# ATA5835 device description
Architecture: AVR8; Family: megaAVR
Registers are 8-bit, access not given, no defined reset value unless marked. A register's access mark holds for its fields unless they carry their own. Offsets are from the block's base; [hi:lo] are bit positions.

## RXBUF
Instances: RXBUF 0x00
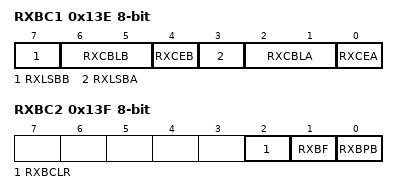
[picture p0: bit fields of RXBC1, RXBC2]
0x13E RXBC1 — Rx Buffer Configuration 1
  [7] RXLSBB — Receive Data LSB-First Path B
  [6:5] RXCBLB — Receive CRC Bit Length Path B
    0=CRC 4-bit; 1=CRC 8-bit; 2=CRC 16-bit
  [4] RXCEB — RX CRC Enable data path B
  [3] RXLSBA — Receive Data LSB-First Path A
  [2:1] RXCBLA — Receive CRC Bit Length Path A
    0=CRC 4-bit; 1=CRC 8-bit; 2=CRC 16-bit
  [0] RXCEA — RX CRC Enable data path A
0x13F RXBC2 — Rx Buffer Configuration 2
  [2] RXBCLR — RX Buffer Clear
  [1] RXBF — RX Buffer Finish
  [0] RXBPB — RX Buffer Path Select
0x140 RXTLLB — Rx Telegram Length Low Byte Path B
0x141 RXTLHB bits used 3:0 — Rx Telegram Length High Byte Path B
0x142 RXCRLB — Rx CRC Result Low Byte Path B
0x143 RXCRHB — Rx CRC Result High Byte Path B
0x144 RXCSBB — Rx CRC Skip Bit Number Path B
0x145 RXCILB — Rx CRC Init Value Low Byte Path B
0x146 RXCIHB — Rx CRC Init Value High Byte Path B
0x147 RXCPLB — Rx CRC Polynomial Low Byte Path B
0x148 RXCPHB — Rx CRC Polynomial High Byte Path B
0x149 RXDSB — Receive Data Shift Register Path B
0x14A RXTLLA — Rx Telegram Length Low Byte Path A
0x14B RXTLHA bits used 3:0 — Rx Telegram Length High Byte Path A
0x14C RXCRLA — Rx CRC Result Low Byte Path A
0x14D RXCRHA — Rx CRC Result High Byte Path A
0x14E RXCSBA — Rx CRC Skip Bit Number Path A
0x14F RXCILA — Rx CRC Init Value Low Byte Path A
0x150 RXCIHA — Rx CRC Init Value High Byte Path A
0x151 RXCPLA — Rx CRC Polynomial Low Byte Path A
0x152 RXCPHA — Rx CRC Polynomial High Byte Path A
0x153 RXDSA — Receive Data Shift Register Path A

## SFIFO
Instances: SFIFO 0x00
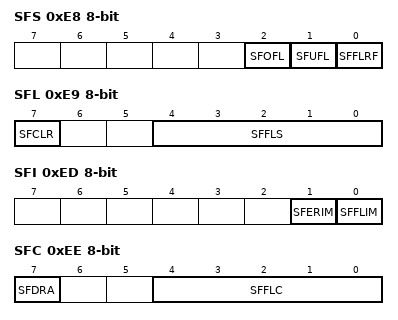
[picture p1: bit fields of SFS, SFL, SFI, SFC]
0xE8 SFS — Support FIFO Status
  [2] SFOFL — Support FIFO Overflow Flag
  [1] SFUFL — Support FIFO Underflow Flag
  [0] SFFLRF — Support FIFO Fill Level Reached Status Flag
0xE9 SFL — Support FIFO Fill Level
  [7] SFCLR — Support FIFO Clear
  [4:0] SFFLS — Support FIFO Fill Level Status
0xEA SFWP bits used 4:0 — Support FIFO Write Pointer
0xEB SFRP bits used 4:0 — Support FIFO Read Pointer
0xEC SFD — Support FIFO Data
0xED SFI — Support FIFO Interrupt Mask
  [1] SFERIM — Support FIFO Error Interrupt Mask
  [0] SFFLIM — Support FIFO Fill Level Interrupt Mask
0xEE SFC — Support FIFO Configuration
  [7] SFDRA — Support FIFO Direct Read Access Operational Mode
  [4:0] SFFLC — Support FIFO Fill Level Configuration

## SPI
Instances: SPI 0x00
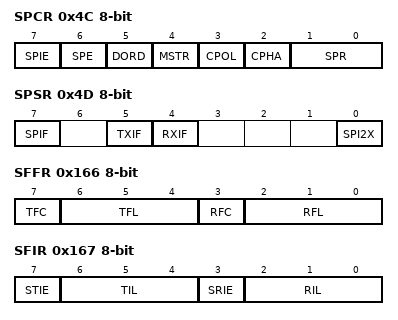
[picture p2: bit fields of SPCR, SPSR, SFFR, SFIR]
0x4C SPCR — SPI Control Register
  [7] SPIE — SPI Interrupt Enable
  [6] SPE — SPI Enable
  [5] DORD — Data Order
  [4] MSTR — Master/Slave Select
  [3] CPOL — Clock Polarity
  [2] CPHA — Clock Phase
  [1:0] SPR — SPI Clock Rate Select
    0=clkio/4; 1=clkio/16; 2=clkio/64; 3=clkio/128; 4=clkio/2; 5=clkio/8; 6=clkio/32; 7=clkio/64
0x4D SPSR — SPI Status Register
  [7] SPIF — SPI Interrupt Flag
  [5] TXIF — Tx Buffer Interrupt Flag
  [4] RXIF — Rx Buffer Interrupt Flag
  [0] SPI2X — Double SPI Speed Bit
0x4E SPDR — SPI Data Register
0x166 SFFR — SPI FIFO Fill Status Register
  [7] TFC — Transmit Buffer Clear
  [6:4] TFL — Transmit Buffer Fill Level
  [3] RFC — Rx Buffer Clear
  [2:0] RFL — Receive Buffer Fill Level
0x167 SFIR — SPI FIFO Interrupt Register
  [7] STIE — SPI Transmit Buffer Interrupt Enable
  [6:4] TIL — Transmit Buffer Interrupt Level
  [3] SRIE — SPI Rx Buffer Interrupt Enable
  [2:0] RIL — Receive Buffer Interrupt Level

## SUP
Instances: SUP 0x00
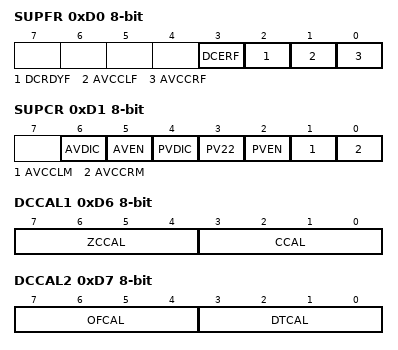
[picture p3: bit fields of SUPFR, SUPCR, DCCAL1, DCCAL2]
0xD0 SUPFR — Supply Flag Register
  [3] DCERF — DCDC Converter Error Flag
  [2] DCRDYF — DCDC Converter Ready Flag
  [1] AVCCLF — AVCC Low Flag
  [0] AVCCRF — AVCC Reset Flag
0xD1 SUPCR — Supply Control Register
  [6] AVDIC — AVCC Double Internal Current
  [5] AVEN — AVCC Enable
  [4] PVDIC — Power Amplifier Regulator Double Internal Current
  [3] PV22 — Power Amplifier Voltage 2.2V
  [2] PVEN — Power Amplifier Voltage Supply Enable
  [1] AVCCLM — AVCC Low Interrupt Mask
  [0] AVCCRM — AVCC Reset Interrupt Mask
0xD6 DCCAL1 — DCDC Converter Calibration 1
  [7:4] ZCCAL — Zero Crossing Calibration
  [3:0] CCAL — Current Limit Calibration
0xD7 DCCAL2 — DCDC Converter Calibration 2
  [7:4] OFCAL — Offset Calibration
  [3:0] DTCAL — Dead Time Calibration
0xD8 DCCAL3 — DCDC Converter Calibration 3
  [1:0] SAWCAL — Ramp Calibration
0xD9 DCTST — DCDC Converter Test Mode
  [4:0] DCTST
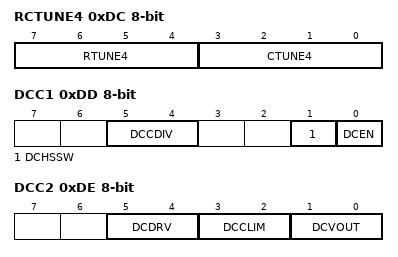
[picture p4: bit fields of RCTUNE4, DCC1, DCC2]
0xDC RCTUNE4 — Resistor Capacitor 4 Bit Tuning
  [7:4] RTUNE4 — 4 Bit Resistor Tuning
  [3:0] CTUNE4 — 4 Bit Capacitor Tuning
0xDD DCC1 — DCDC Converter Control 1
  [5:4] DCCDIV — DCDC Converter Clock Divider
    0=16 (375kHz); 1=12 (500kHz); 2=8 (750kHz); 3=6 (1MHz)
  [1] DCHSSW — DCDC Converter High Side Switch
  [0] DCEN — DCDC Converter Enable
0xDE DCC2 — DCDC Converter Control 2
  [5:4] DCDRV — DCDC Converter Driver Strength
  [3:2] DCCLIM — DCDC Converter Current Limit
  [1:0] DCVOUT — DCDC Converter Output Voltage
    0=2.2V; 1=2.5V; 2=2.8V; 3=3.3V
